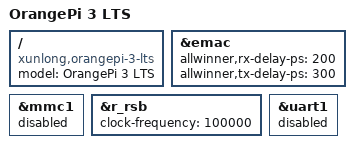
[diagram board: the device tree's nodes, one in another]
// SPDX-License-Identifier: (GPL-2.0+ OR MIT)
// Copyright (C) 2023 Jernej Skrabec <jernej.skrabec@gmail.com>

#include "sun50i-h6-orangepi-3.dts"

/ {
	model = "OrangePi 3 LTS";
	compatible = "xunlong,orangepi-3-lts", "allwinner,sun50i-h6";
};

&emac {
	allwinner,rx-delay-ps = <200>;
	allwinner,tx-delay-ps = <300>;
};

&mmc1 {
	status = "disabled";
};

&r_rsb {
	clock-frequency = <100000>;
};

&uart1 {
	status = "disabled";
};
